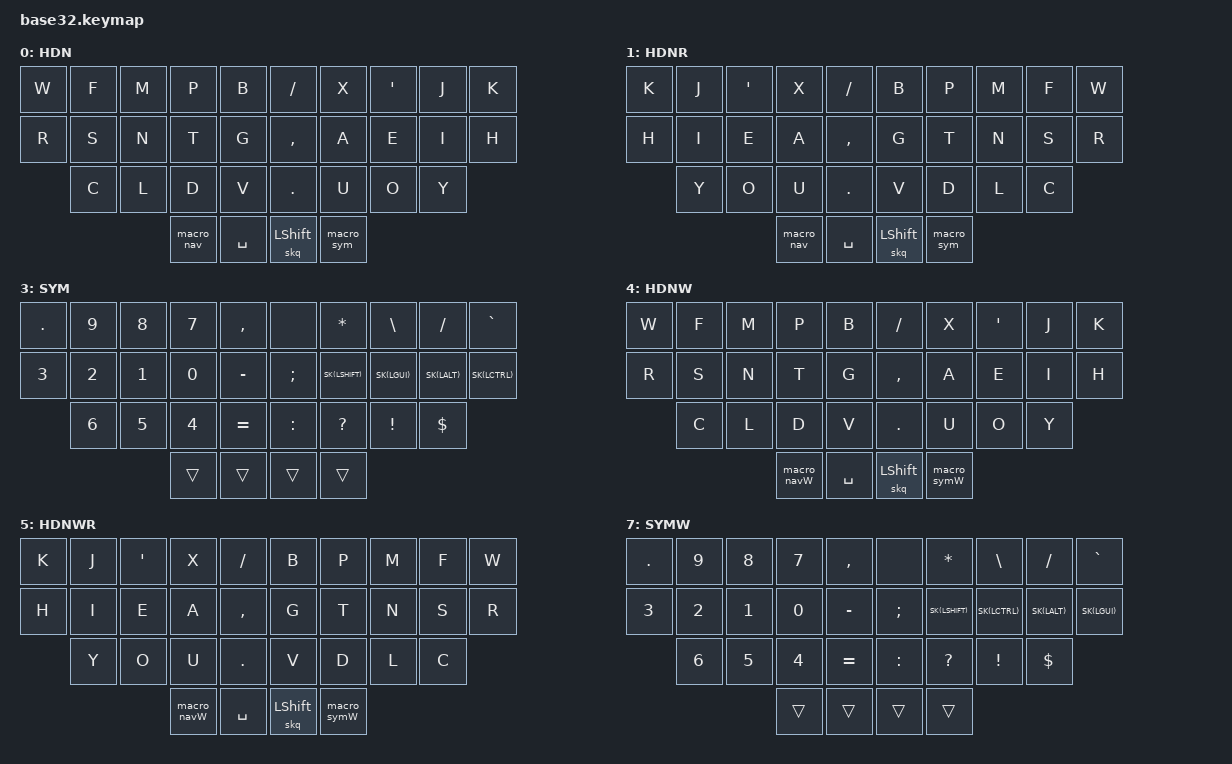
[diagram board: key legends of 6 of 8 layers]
/*
 * Copyright (c) 2020 The ZMK Contributors
 *
 * SPDX-License-Identifier: MIT
 */

#include <behaviors.dtsi>
#include <dt-bindings/zmk/keys.h>
#include <dt-bindings/zmk/bt.h>
#include <dt-bindings/zmk/outputs.h>

#define HDN 0
#define HDNR 1
#define NAV 2
#define SYM 3
#define HDNW 4
#define HDNWR 5
#define NAVW 6
#define SYMW 7

#define SK(KEY) &nk KEY KEY
// Keep sticky keys active for a long time so they effectively do not time out
#define STICKY_KEY_TIMEOUT 60000

&sk {
  release-after-ms = <STICKY_KEY_TIMEOUT>;
};

&caps_word {
  continue-list = <UNDERSCORE MINUS BACKSPACE>;
};

/*                KEY POSITIONS

  ╭────────────────────╮ ╭────────────────────╮
  │  0   1   2   3   4 │ │  5   6   7   8   9 │
  │ 10  11  12  13  14 │ │ 15  16  17  18  19 │
  │     20  21  22  23 │ │ 24  25  26  27     │
  ╰───────────╮ 28  29 │ │ 30  31 ╭───────────╯
              ╰────────╯ ╰────────╯            */

/ { 
  
                
  combos {
    #include "combos32.dtsi"
  };
  
  macros {
    #include "macros.dtsi"
  };

  behaviors {
    // Sticky key on tap, normal key on hold
    // Useful for modifier-clicking without the modifier remaining active
     nk: not_so_sticky_key {
       compatible = "zmk,behavior-hold-tap";
       label = "NOT_SO_STICKY_KEY";
       #binding-cells = <2>;
       tapping_term_ms = <200>;
       flavor = "tap-preferred";
       bindings = <&kp>, <&sk>;
     };

    skq: sticky_key_quick_release {
      compatible = "zmk,behavior-sticky-key";
      label = "STICKY_KEY_QUICK_RELEASE";
      #binding-cells = <1>;
      bindings = <&kp>;
      quick-release;
      release-after-ms = <STICKY_KEY_TIMEOUT>;
    };


  };
 
        keymap {
                compatible = "zmk,keymap";
                      
        handsdown {
            label = "HDN";
            bindings = <
// ╭─────────────┬─────────────┬─────────────┬─────────────┬─────────────╮   ╭─────────────┬─────────────┬─────────────┬─────────────┬─────────────╮
         &kp W       &kp F         &kp M         &kp P         &kp B             &kp SLASH     &kp X         &kp SQT       &kp J      &kp K
         &kp R       &kp S         &kp N         &kp T         &kp G             &kp COMMA     &kp A         &kp E         &kp I      &kp H         
                     &kp C         &kp L         &kp D         &kp V             &kp DOT       &kp U         &kp O         &kp Y         
// ╰─────────────┴─────────────┴─────────────┼─────────────┼─────────────┤   ├─────────────┼─────────────┼─────────────┴─────────────┴─────────────╯
                                               &macro_nav    &kp SPACE         &skq LSHIFT    &macro_sym
//                                           ╰─────────────┴─────────────╯   ╰─────────────┴─────────────╯
            >;
        };

        handsdown_reversed {
            label = "HDNR";
            bindings = <
// ╭─────────────┬─────────────┬─────────────┬─────────────┬─────────────╮   ╭─────────────┬─────────────┬─────────────┬─────────────┬─────────────╮
     &kp K         &kp J         &kp SQT       &kp X         &kp SLASH         &kp B          &kp P         &kp M        &kp F         &kp W                           
     &kp H         &kp I         &kp E         &kp A         &kp COMMA         &kp G          &kp T         &kp N        &kp S         &kp R                                   
                   &kp Y         &kp O         &kp U         &kp DOT           &kp V          &kp D         &kp L        &kp C                                   
// ╰─────────────┴─────────────┴─────────────┼─────────────┼─────────────┤   ├─────────────┼─────────────┼─────────────┴─────────────┴─────────────╯
                                               &macro_nav    &kp SPACE         &skq LSHIFT    &macro_sym
//                                           ╰─────────────┴─────────────╯   ╰─────────────┴─────────────╯
            >;
        };

        navitation {
            label = "NAV";
            bindings = <
// ╭─────────────┬─────────────┬─────────────┬─────────────┬─────────────╮   ╭─────────────┬─────────────┬─────────────┬─────────────┬─────────────╮
&kp LG(LC(LA(LS(P))))  &kp ENTER   &kp BACKSPACE  &kp TAB       &kp LA(BACKSPACE)  &kp LA(BACKSPACE) &none         &kp UP        &kp LG(Q)      &none
         SK(LCTL)      SK(LALT)    SK(LGUI)       SK(LSHIFT)    &kp DELETE         &none             &kp LEFT      &kp DOWN      &kp RIGHT      &none 
                       &kp LG(X)   &kp LG(C)      &kp LG(V)     &kp LG(A)          &kp LG(A)         &kp ENTER     &kp BACKSPACE &kp TAB      
// ╰─────────────┴─────────────┴─────────────┼─────────────┼─────────────┤   ├─────────────┼─────────────┼─────────────┴─────────────┴─────────────╯
                                               &trans         &trans            &trans        &trans
//                                           ╰─────────────┴─────────────╯   ╰─────────────┴─────────────╯
            >;
        };
        symbols {
            label = "SYM";
            bindings = <
// ╭─────────────┬─────────────┬─────────────┬─────────────┬─────────────╮   ╭─────────────┬─────────────┬─────────────┬─────────────┬─────────────╮
          &kp DOT    &kp N9       &kp N8         &kp N7         &kp COMMA         &none        &kp ASTRK     &kp BSLH     &kp SLASH     &kp GRAVE
          &kp N3     &kp N2       &kp N1         &kp N0         &kp MINUS         &kp SEMI     SK(LSHIFT)    SK(LGUI)     SK(LALT)      SK(LCTRL)
                     &kp N6       &kp N5         &kp N4         &kp EQUAL         &kp COLON    &kp QMARK     &kp EXCL     &kp DLLR       
// ╰─────────────┴─────────────┴─────────────┼─────────────┼─────────────┤   ├─────────────┼─────────────┼─────────────┴─────────────┴─────────────╯
                                               &trans         &trans            &trans       &trans
//                                           ╰─────────────┴─────────────╯   ╰─────────────┴─────────────╯
            >;
        };

        handsdown_windows {
            label = "HDNW";
            bindings = <
// ╭─────────────┬─────────────┬─────────────┬─────────────┬─────────────╮   ╭─────────────┬─────────────┬─────────────┬─────────────┬─────────────╮
           &kp W      &kp F         &kp M         &kp P         &kp B             &kp SLASH     &kp X         &kp SQT       &kp J      &kp K
           &kp R      &kp S         &kp N         &kp T         &kp G             &kp COMMA     &kp A         &kp E         &kp I      &kp H       
                      &kp C         &kp L         &kp D         &kp V             &kp DOT       &kp U         &kp O         &kp Y         
// ╰─────────────┴─────────────┴─────────────┼─────────────┼─────────────┤   ├─────────────┼─────────────┼─────────────┴─────────────┴─────────────╯
                                               &macro_navW   &kp SPACE         &skq LSHIFT    &macro_symW
//                                           ╰─────────────┴─────────────╯   ╰─────────────┴─────────────╯
            >;
        };

        handsdown_windows_reversed {
            label = "HDNWR";
            bindings = <
// ╭─────────────┬─────────────┬─────────────┬─────────────┬─────────────╮   ╭─────────────┬─────────────┬─────────────┬─────────────┬─────────────╮
     &kp K         &kp J         &kp SQT       &kp X         &kp SLASH         &kp B          &kp P         &kp M        &kp F         &kp W                           
     &kp H         &kp I         &kp E         &kp A         &kp COMMA         &kp G          &kp T         &kp N        &kp S         &kp R                                   
                   &kp Y         &kp O         &kp U         &kp DOT           &kp V          &kp D         &kp L        &kp C 
// ╰─────────────┴─────────────┴─────────────┼─────────────┼─────────────┤   ├─────────────┼─────────────┼─────────────┴─────────────┴─────────────╯
                                               &macro_navW   &kp SPACE         &skq LSHIFT    &macro_symW
//                                           ╰─────────────┴─────────────╯   ╰─────────────┴─────────────╯
            >;
        };

        navigation_windows {
            label = "NAVW";
            bindings = <
// ╭─────────────┬─────────────┬─────────────┬─────────────┬─────────────╮   ╭─────────────┬─────────────┬─────────────┬─────────────┬─────────────╮
&kp LC(LA(LS(P)))  &kp ENTER     &kp BACKSPACE  &kp TAB      &kp LC(BACKSPACE)   &kp LC(BACKSPACE)  &kp F2         &kp UP        &kp LA(F4)    &none  
      SK(LGUI)     SK(LALT)      SK(LCTRL)      SK(LSHIFT)   &kp DELETE          &none              &kp LEFT      &kp DOWN      &kp RIGHT     &none 
                   &kp LC(X)     &kp LC(C)      &kp LC(V)    &kp LC(A)           &kp LC(A)          &kp ENTER     &kp BACKSPACE &kp TAB       
// ╰─────────────┴─────────────┴─────────────┼─────────────┼─────────────┤   ├─────────────┼─────────────┼─────────────┴─────────────┴─────────────╯
                                               &trans          &trans            &trans        &trans
//                                           ╰─────────────┴─────────────╯   ╰─────────────┴─────────────╯
            >;
        };

        symbols_windows {
            label = "SYMW";
            bindings = <
// ╭─────────────┬─────────────┬─────────────┬─────────────┬─────────────╮   ╭─────────────┬─────────────┬─────────────┬─────────────┬─────────────╮
            &kp DOT     &kp N9     &kp N8       &kp N7       &kp COMMA         &none         &kp ASTRK     &kp BSLH     &kp SLASH      &kp GRAVE      
            &kp N3      &kp N2     &kp N1       &kp N0       &kp MINUS         &kp SEMI      SK(LSHIFT)    SK(LCTRL)     SK(LALT)      SK(LGUI) 
                        &kp N6     &kp N5       &kp N4       &kp EQUAL         &kp COLON     &kp QMARK     &kp EXCL     &kp DLLR
// ╰─────────────┴─────────────┴─────────────┼─────────────┼─────────────┤   ├─────────────┼─────────────┼─────────────┴─────────────┴─────────────╯
                                               &trans        &trans            &trans        &trans
//                                           ╰─────────────┴─────────────╯   ╰─────────────┴─────────────╯
            >;
        };
};

};
